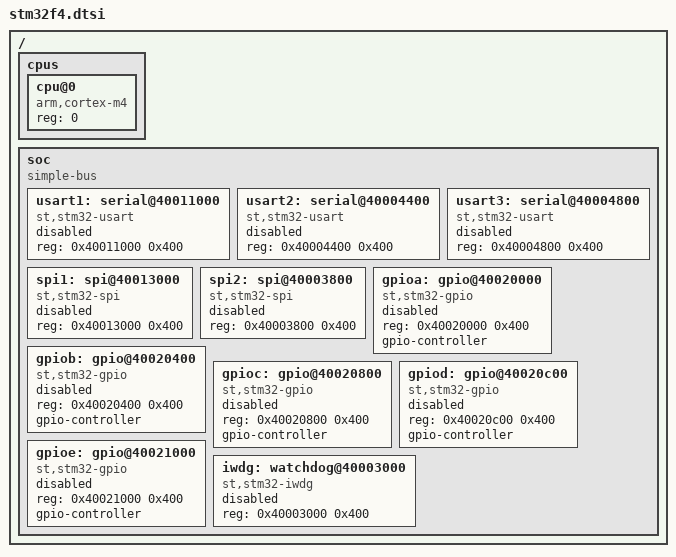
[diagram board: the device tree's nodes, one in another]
/*
 * Shared STM32F4 SoC description for Ark RTOS boards.
 *
 * Only what a board actually needs is listed, and every peripheral starts
 * "disabled": a board file enables the ones it wires up.  Register windows are
 * the Cortex-M4 peripheral addresses from the STM32F4 reference manual; they
 * are hardware facts, not a memory layout choice, so they belong here and not
 * in config/arkrtos_partition.h.
 */

/ {
	#address-cells = <1>;
	#size-cells = <1>;

	cpus {
		#address-cells = <1>;
		#size-cells = <0>;

		cpu@0 {
			compatible = "arm,cortex-m4";
			reg = <0>;
		};
	};

	soc {
		compatible = "simple-bus";
		#address-cells = <1>;
		#size-cells = <1>;

		usart1: serial@40011000 {
			compatible = "st,stm32-usart";
			reg = <0x40011000 0x400>;
			status = "disabled";
		};

		usart2: serial@40004400 {
			compatible = "st,stm32-usart";
			reg = <0x40004400 0x400>;
			status = "disabled";
		};

		usart3: serial@40004800 {
			compatible = "st,stm32-usart";
			reg = <0x40004800 0x400>;
			status = "disabled";
		};

		spi1: spi@40013000 {
			compatible = "st,stm32-spi";
			reg = <0x40013000 0x400>;
			#address-cells = <1>;
			#size-cells = <0>;
			status = "disabled";
		};

		spi2: spi@40003800 {
			compatible = "st,stm32-spi";
			reg = <0x40003800 0x400>;
			#address-cells = <1>;
			#size-cells = <0>;
			status = "disabled";
		};

		gpioa: gpio@40020000 {
			compatible = "st,stm32-gpio";
			reg = <0x40020000 0x400>;
			gpio-controller;
			#gpio-cells = <2>;
			status = "disabled";
		};

		gpiob: gpio@40020400 {
			compatible = "st,stm32-gpio";
			reg = <0x40020400 0x400>;
			gpio-controller;
			#gpio-cells = <2>;
			status = "disabled";
		};

		gpioc: gpio@40020800 {
			compatible = "st,stm32-gpio";
			reg = <0x40020800 0x400>;
			gpio-controller;
			#gpio-cells = <2>;
			status = "disabled";
		};

		gpiod: gpio@40020c00 {
			compatible = "st,stm32-gpio";
			reg = <0x40020c00 0x400>;
			gpio-controller;
			#gpio-cells = <2>;
			status = "disabled";
		};

		gpioe: gpio@40021000 {
			compatible = "st,stm32-gpio";
			reg = <0x40021000 0x400>;
			gpio-controller;
			#gpio-cells = <2>;
			status = "disabled";
		};

		iwdg: watchdog@40003000 {
			compatible = "st,stm32-iwdg";
			reg = <0x40003000 0x400>;
			status = "disabled";
		};
	};
};
